# NM1500_v1 register map
File version: 1.0
Registers are 32-bit, read-write, reset 0x0 unless marked. A register's access mark holds for its fields unless they carry their own. Offsets are from the block's base; [hi:lo] are bit positions; {n}, {i} and the like mark numbered series.

## INT — INT Register Map
Base 0x50000300
0x00 IRQ0_SRC ro reset not defined — IRQ0 (BOD) interrupt source identity
  [0] BOD_INT — Identify BOD interrupt source.
0x04 IRQ1_SRC ro reset not defined — IRQ1 (WDT) interrupt source identity
  [0] WDT_INT — Identify WDT interrupt source.
0x08 IRQ2_SRC ro reset not defined — IRQ2 (EINT0) interrupt source identity
  [0] EINT0 — Identify EINT0 interrupt source. EINT0 is external interrupt 0 from P3.2.
0x0C IRQ3_SRC ro reset not defined — IRQ3 (EINT1) interrupt source identity
  [0] EINT1 — Identify EINT1 interrupt source. EINT1 is external interrupt from P3.3.
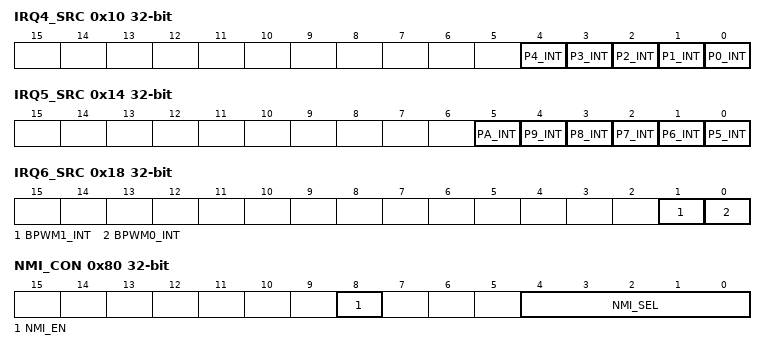
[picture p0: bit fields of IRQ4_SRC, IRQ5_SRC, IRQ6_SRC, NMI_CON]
0x10 IRQ4_SRC ro reset not defined — IRQ4 (P0-P4) interrupt source identity
  [n] P{n}_INT (n=0..4) — Identify P{n} interrupt source.
0x14 IRQ5_SRC ro reset not defined — IRQ5 (P5-PA) interrupt source identity
  [5] PA_INT — Identify PA interrupt source.
  [n-5] P{n}_INT (n=5..9) — Identify P{n} interrupt source.
0x18 IRQ6_SRC ro reset not defined — IRQ6 (BPWM) interrupt source identity
  [1] BPWM1_INT — Identify BPWM1 interrupt source.
  [0] BPWM0_INT — Identify BPWM0 interrupt source.
0x1C IRQ7_SRC ro reset not defined — IRQ7 (ADC0) interrupt source identity
  [0] ADC0_INT — Identify ADC0 interrupt source.
{0x0+4i} IRQ{i}_SRC ro reset not defined (i=8..11) — IRQ{i} (TMR{i-8}) interrupt source identity
  [0] TMR{i-8}_INT — Identify TMR{i-8} interrupt source.
0x30 IRQ12_SRC ro reset not defined — IRQ12 (UART0) interrupt source identity
  [0] UART0_INT — Identify UART0 interrupt source.
0x34 IRQ13_SRC ro reset not defined — IRQ13 (UART1) interrupt source identity
  [0] UART1_INT — Identify UART1 interrupt source.
{0x0+4i} IRQ{i}_SRC ro reset not defined (i=14..16) — IRQ{i} (SPI{i-14}) interrupt source identity
  [0] SPI{i-14}_INT — Identify SPI{i-14} interrupt source.
0x44 IRQ17_SRC ro reset not defined — IRQ17 (MDU) interrupt source identity
  [0] MDU_INT — Identify MDU interrupt source.
0x48 IRQ18_SRC ro reset not defined — IRQ18 (I2C) interrupt source identity
  [0] I2C_INT — Identify I2C0 interrupt source.
0x4C IRQ19_SRC ro reset not defined — IRQ19 (Reserved) interrupt source identity
0x50 IRQ20_SRC ro reset not defined — IRQ20 (CAN) interrupt source identity
  [0] CAN_INT — Identify CAN interrupt source.
0x54 IRQ21_SRC ro reset not defined — IRQ21 (EPWM0) interrupt source identity
  [0] EPWM0_INT — Identify EPWM0 interrupt source.
0x58 IRQ22_SRC ro reset not defined — IRQ22 (EPWM1) interrupt source identity
  [0] EPWM1_INT — Identify EPWM1 interrupt source.
0x5C IRQ23_SRC ro reset not defined — IRQ23 (CAP0) interrupt source identity
  [0] CAP0_INT — Identify CAP0 interrupt source.
0x60 IRQ24_SRC ro reset not defined — IRQ24 (CAP1) interrupt source identity
  [0] CAP1_INT — Identify CAP1 interrupt source.
0x64 IRQ25_SRC ro reset not defined — IRQ25 (ACMP) interrupt source identity
  [0] ACMP_INT — Identify ACMP interrupt source.
0x68 IRQ26_SRC ro reset not defined — IRQ26 (QEI0) interrupt source identity
  [0] QEI0_INT — Identify QEI0 interrupt source.
0x6C IRQ27_SRC ro reset not defined — IRQ27 (QEI1) interrupt source identity
  [0] QEI1_INT — Identify QEI1 interrupt source.
0x70 IRQ28_SRC ro reset not defined — IRQ28 (PWRWU) interrupt source identity
  [0] PWRWU_INT — Identify PWRWU interrupt source.
{0x0+4i} IRQ{i}_SRC ro reset not defined (i=29..31) — IRQ{i} (ADC{i-28}) interrupt source identity
  [0] ADC{i-28}_INT — Identify ADC{i-28} interrupt source.
0x80 NMI_CON — NMI interrupt control register
  [8] NMI_EN — NMI Interrupt Enable
    0=IRQ0~31 assigned to NMI Disabled. (NMI still can be software triggered by setting its pending flag.); 1=IRQ0~31 assigned to NMI Enabled
  [4:0] NMI_SEL — NMI Interrupt Source Selection. The NMI interrupt to Cortex-M0 can be selected from one of IRQ0~IRQ31 by setting NMI_SEL with IRQ number. The default NMI interrupt is assigned as IRQ0 interrupt if NMI is enabled by setting NMI_SEL[8].
0x84 MCU_IRQ — MCU interrupt request source register
  [31:0] MCU_IRQ — MCU IRQ Source Register. The MCU_IRQ collects all the interrupts from the peripherals and generates the synchronous interrupt to Cortex-M0. The MCU_IRQ collects all interrupts from each peripheral and synchronizes them and then interrupts the Cortex-M0. When the MCU_IRQ[n] is 0:
    0=No effect; 1=Generate an interrupt to Cortex_M0 NVIC[n]. Clear the interrupt and MCU_IRQ[n]
